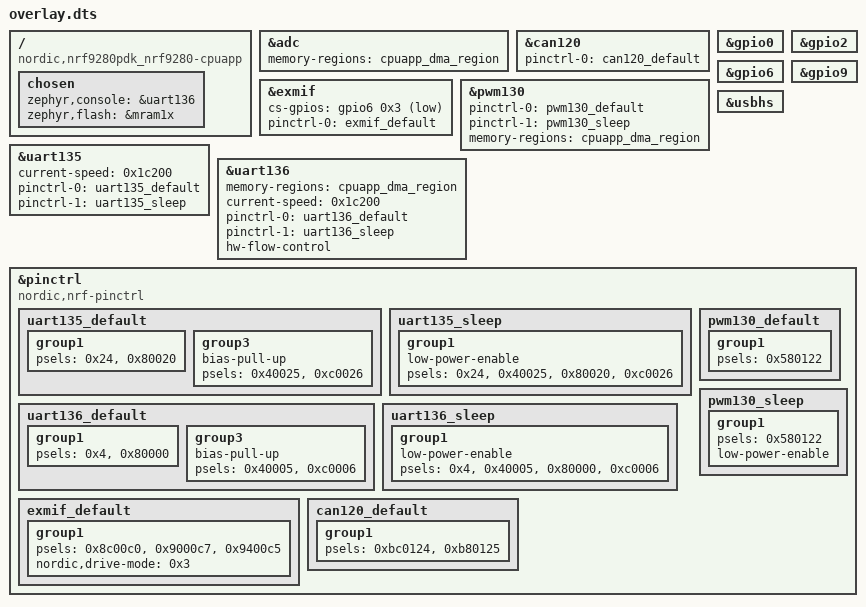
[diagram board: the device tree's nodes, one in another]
/ {
	compatible = "nordic,nrf9280pdk_nrf9280-cpuapp";
	chosen {
		zephyr,console = &uart136;
		zephyr,flash = &mram1x;
	};
};
&adc{
	status = "okay";
	memory-regions = < &cpuapp_dma_region >;
};
&can120{
	status = "okay";
	pinctrl-0 = < &can120_default >;
	pinctrl-names = "default";
};
&exmif{
	status = "okay";
	cs-gpios = < &gpio6 0x3 0x1 >;
	pinctrl-0 = < &exmif_default >;
	pinctrl-names = "default";
};
&gpio0{
	status = "okay";
};
&gpio2{
	status = "okay";
};
&gpio6{
	status = "okay";
};
&gpio9{
	status = "okay";
};
&pwm130{
	status = "okay";
	pinctrl-0 = < &pwm130_default >;
	pinctrl-1 = < &pwm130_sleep >;
	pinctrl-names = "default", "sleep";
	memory-regions = < &cpuapp_dma_region >;
};
&uart135{
	current-speed = < 0x1c200 >;
	pinctrl-0 = < &uart135_default >;
	pinctrl-1 = < &uart135_sleep >;
	pinctrl-names = "default", "sleep";
};
&uart136{
	status = "okay";
	memory-regions = < &cpuapp_dma_region >;
	current-speed = < 0x1c200 >;
	pinctrl-0 = < &uart136_default >;
	pinctrl-1 = < &uart136_sleep >;
	pinctrl-names = "default", "sleep";
	hw-flow-control;
};
&usbhs{
	status = "okay";
};
&pinctrl{
	compatible = "nordic,nrf-pinctrl";
	uart135_default: uart135_default {
		group1 {
			psels = < 0x24 >, < 0x80020 >;
		};
		group3 {
			bias-pull-up;
			psels = < 0x40025 >, < 0xc0026 >;
		};
	};
	uart135_sleep: uart135_sleep {
		group1 {
			low-power-enable;
			psels = < 0x24 >, < 0x40025 >, < 0x80020 >, < 0xc0026 >;
		};
	};
	uart136_default: uart136_default {
		group1 {
			psels = < 0x4 >, < 0x80000 >;
		};
		group3 {
			bias-pull-up;
			psels = < 0x40005 >, < 0xc0006 >;
		};
	};
	uart136_sleep: uart136_sleep {
		group1 {
			low-power-enable;
			psels = < 0x4 >, < 0x40005 >, < 0x80000 >, < 0xc0006 >;
		};
	};
	exmif_default: exmif_default {
		group1 {
			psels = < 0x8c00c0 >, < 0x9000c7 >, < 0x9400c5 >;
			nordic,drive-mode = < 0x3 >;
		};
	};
	can120_default: can120_default {
		group1 {
			psels = < 0xbc0124 >, < 0xb80125 >;
		};
	};
	pwm130_default: pwm130_default {
		group1 {
			psels = < 0x580122 >;
		};
	};
	pwm130_sleep: pwm130_sleep {
		group1 {
			psels = < 0x580122 >;
			low-power-enable;
		};
	};
};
